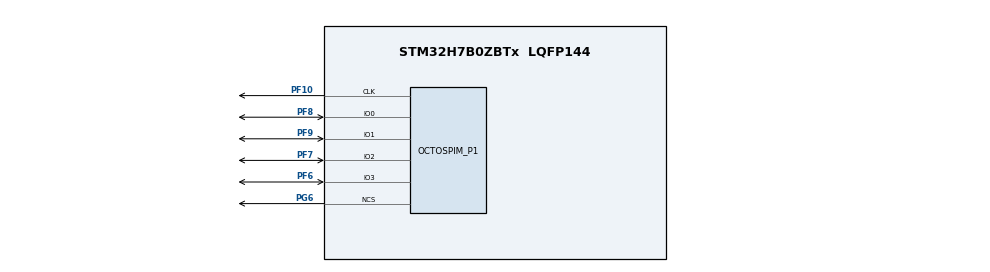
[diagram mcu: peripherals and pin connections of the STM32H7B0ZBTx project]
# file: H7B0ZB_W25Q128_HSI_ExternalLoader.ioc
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CORTEX_M7.AccessPermission_S-Cortex_Memory_Protection_Unit_Region1_Settings_S=MPU_REGION_FULL_ACCESS
CORTEX_M7.AccessPermission_S-Cortex_Memory_Protection_Unit_Region2_Settings_S=MPU_REGION_FULL_ACCESS
CORTEX_M7.AccessPermission_S-Cortex_Memory_Protection_Unit_Region3_Settings_S=MPU_REGION_FULL_ACCESS
CORTEX_M7.AccessPermission_S-Cortex_Memory_Protection_Unit_Region4_Settings_S=MPU_REGION_FULL_ACCESS
CORTEX_M7.AccessPermission_S-Cortex_Memory_Protection_Unit_Region5_Settings_S=MPU_REGION_FULL_ACCESS
CORTEX_M7.AccessPermission_S-Cortex_Memory_Protection_Unit_Region6_Settings_S=MPU_REGION_FULL_ACCESS
CORTEX_M7.AccessPermission_Spec=MPU_REGION_FULL_ACCESS
CORTEX_M7.BaseAddress_S-Cortex_Memory_Protection_Unit_Region1_Settings_S=0x90000000
CORTEX_M7.BaseAddress_S-Cortex_Memory_Protection_Unit_Region2_Settings_S=0x20000000
CORTEX_M7.BaseAddress_S-Cortex_Memory_Protection_Unit_Region3_Settings_S=0x24000000
CORTEX_M7.BaseAddress_S-Cortex_Memory_Protection_Unit_Region4_Settings_S=0x24000000
CORTEX_M7.BaseAddress_S-Cortex_Memory_Protection_Unit_Region5_Settings_S=0x30000000
CORTEX_M7.BaseAddress_S-Cortex_Memory_Protection_Unit_Region6_Settings_S=0x38000000
CORTEX_M7.BaseAddress_Spec=0x08000000
CORTEX_M7.CPU_DCache=Disabled
CORTEX_M7.CPU_ICache=Disabled
CORTEX_M7.DisableExec_S-Cortex_Memory_Protection_Unit_Region4_Settings_S=MPU_INSTRUCTION_ACCESS_ENABLE
CORTEX_M7.DisableExec_Spec=MPU_INSTRUCTION_ACCESS_ENABLE
CORTEX_M7.Enable_S-Cortex_Memory_Protection_Unit_Region1_Settings_S=MPU_REGION_ENABLE
CORTEX_M7.Enable_S-Cortex_Memory_Protection_Unit_Region2_Settings_S=MPU_REGION_ENABLE
CORTEX_M7.Enable_S-Cortex_Memory_Protection_Unit_Region3_Settings_S=MPU_REGION_ENABLE
CORTEX_M7.Enable_S-Cortex_Memory_Protection_Unit_Region4_Settings_S=MPU_REGION_ENABLE
CORTEX_M7.Enable_S-Cortex_Memory_Protection_Unit_Region5_Settings_S=MPU_REGION_ENABLE
CORTEX_M7.Enable_S-Cortex_Memory_Protection_Unit_Region6_Settings_S=MPU_REGION_ENABLE
CORTEX_M7.Enable_S-Cortex_Memory_Protection_Unit_Region7_Settings_S=__NULL
CORTEX_M7.Enable_S-Cortex_Memory_Protection_Unit_Region8_Settings_S=__NULL
CORTEX_M7.IsBufferable_S-Cortex_Memory_Protection_Unit_Region1_Settings_S=MPU_ACCESS_BUFFERABLE
CORTEX_M7.IsBufferable_S-Cortex_Memory_Protection_Unit_Region2_Settings_S=MPU_ACCESS_NOT_BUFFERABLE
CORTEX_M7.IsBufferable_S-Cortex_Memory_Protection_Unit_Region3_Settings_S=MPU_ACCESS_BUFFERABLE
CORTEX_M7.IsBufferable_S-Cortex_Memory_Protection_Unit_Region4_Settings_S=MPU_ACCESS_NOT_BUFFERABLE
CORTEX_M7.IsBufferable_S-Cortex_Memory_Protection_Unit_Region5_Settings_S=MPU_ACCESS_BUFFERABLE
CORTEX_M7.IsBufferable_S-Cortex_Memory_Protection_Unit_Region6_Settings_S=MPU_ACCESS_NOT_BUFFERABLE
CORTEX_M7.IsBufferable_Spec=MPU_ACCESS_BUFFERABLE
CORTEX_M7.IsCacheable_S-Cortex_Memory_Protection_Unit_Region1_Settings_S=MPU_ACCESS_CACHEABLE
CORTEX_M7.IsCacheable_S-Cortex_Memory_Protection_Unit_Region2_Settings_S=MPU_ACCESS_NOT_CACHEABLE
CORTEX_M7.IsCacheable_S-Cortex_Memory_Protection_Unit_Region3_Settings_S=MPU_ACCESS_CACHEABLE
CORTEX_M7.IsCacheable_S-Cortex_Memory_Protection_Unit_Region4_Settings_S=MPU_ACCESS_NOT_CACHEABLE
CORTEX_M7.IsCacheable_S-Cortex_Memory_Protection_Unit_Region5_Settings_S=MPU_ACCESS_CACHEABLE
CORTEX_M7.IsCacheable_S-Cortex_Memory_Protection_Unit_Region6_Settings_S=MPU_ACCESS_NOT_CACHEABLE
CORTEX_M7.IsCacheable_Spec=MPU_ACCESS_CACHEABLE
CORTEX_M7.IsShareable_S-Cortex_Memory_Protection_Unit_Region3_Settings_S=MPU_ACCESS_NOT_SHAREABLE
CORTEX_M7.IsShareable_S-Cortex_Memory_Protection_Unit_Region5_Settings_S=MPU_ACCESS_NOT_SHAREABLE
CORTEX_M7.IsShareable_S-Cortex_Memory_Protection_Unit_Region6_Settings_S=MPU_ACCESS_NOT_SHAREABLE
CORTEX_M7.IsShareable_Spec=MPU_ACCESS_NOT_SHAREABLE
CORTEX_M7.Size_S-Cortex_Memory_Protection_Unit_Region1_Settings_S=MPU_REGION_SIZE_128MB
CORTEX_M7.Size_S-Cortex_Memory_Protection_Unit_Region2_Settings_S=MPU_REGION_SIZE_128KB
CORTEX_M7.Size_S-Cortex_Memory_Protection_Unit_Region3_Settings_S=MPU_REGION_SIZE_1MB
CORTEX_M7.Size_S-Cortex_Memory_Protection_Unit_Region4_Settings_S=MPU_REGION_SIZE_1MB
CORTEX_M7.Size_S-Cortex_Memory_Protection_Unit_Region5_Settings_S=MPU_REGION_SIZE_128KB
CORTEX_M7.Size_S-Cortex_Memory_Protection_Unit_Region6_Settings_S=MPU_REGION_SIZE_32KB
CORTEX_M7.Size_Spec=MPU_REGION_SIZE_256KB
CORTEX_M7.SubRegionDisable_Spec=0
CORTEX_M7.default_mode_Activation=0
Mcu.Family=STM32H7
Mcu.Name=STM32H7B0ZBTx
Mcu.Package=LQFP144
NVIC.PriorityGroup=NVIC_PRIORITYGROUP_4
OCTOSPI1.ChipSelectHighTime=2
OCTOSPI1.ClockPrescaler=1
OCTOSPI1.DeviceSize=23
PA13.Mode=Serial_Wire
PA13.Signal=DEBUG_JTMS-SWDIO
PA14.Mode=Serial_Wire
PA14.Signal=DEBUG_JTCK-SWCLK
PF10.Mode=O1_P1_CLK
PF10.Signal=OCTOSPIM_P1_CLK
PF6.Mode=OCTOSPI1_IOL_Port1L
PF6.Signal=OCTOSPIM_P1_IO3
PF7.Mode=OCTOSPI1_IOL_Port1L
PF7.Signal=OCTOSPIM_P1_IO2
PF8.Mode=OCTOSPI1_IOL_Port1L
PF8.Signal=OCTOSPIM_P1_IO0
PF9.Mode=OCTOSPI1_IOL_Port1L
PF9.Signal=OCTOSPIM_P1_IO1
PG6.Mode=OCTOSPI1_Port1_NCS
PG6.Signal=OCTOSPIM_P1_NCS
ProjectManager.HeapSize=0x200
ProjectManager.StackSize=0x1000
ProjectManager.TargetToolchain=STM32CubeIDE
RCC.ADCFreq_Value=128000000
RCC.APB1Freq_Value=32000000
RCC.APB2Freq_Value=32000000
RCC.APB3Freq_Value=32000000
RCC.APB4Freq_Value=32000000
RCC.CDPPRE=RCC_APB3_DIV2
RCC.CDPPRE1=RCC_APB1_DIV2
RCC.CDPPRE2=RCC_APB2_DIV2
RCC.CortexFreq_Value=64000000
RCC.DIVM1=2
RCC.DIVM2=2
RCC.DIVM3=6
RCC.DIVN1=40
RCC.DIVN2=16
RCC.DIVN3=58
RCC.DIVP2=4
RCC.DIVP3=10
RCC.DIVQ2=8
RCC.DIVQ3=24
RCC.DIVR2=4
RCC.DIVR3=10
RCC.FDCANCLockSelection=RCC_FDCANCLKSOURCE_PLL2
RCC.HCLKFreq_Value=64000000
RCC.HSE_VALUE=25000000
RCC.LPUART1CLockSelection=RCC_LPUART1CLKSOURCE_CSI
RCC.PLL1_VCI_Range-AdvancedSettings=RCC_PLL1VCIRANGE_0
RCC.PLL1_VCO_SEL-AdvancedSettings=RCC_PLL1VCOMEDIUM
RCC.PLL2FRACN=0
RCC.PLL2_VCI_Range-AdvancedSettings=RCC_PLL2VCIRANGE_0
RCC.PLL2_VCO_SEL-AdvancedSettings=RCC_PLL2VCOWIDE
RCC.PLL3FRACN=8048
RCC.PLLFRACN=0
RCC.SAI2ACLockSelection=RCC_SAI2ACLKSOURCE_PLL3
RCC.SAI2BCLockSelection=RCC_SAI2BCLKSOURCE_PLL3
RCC.SDMMC1CLockSelection=RCC_SDMMCCLKSOURCE_PLL2
RCC.SPI123CLockSelection=RCC_SPI123CLKSOURCE_PLL2
RCC.SRDPPRE=RCC_APB4_DIV2
RCC.SYSCLKFreq_VALUE=64000000
RCC.USART234578CLockSelection=RCC_USART234578CLKSOURCE_PLL3
RCC.USBCLockSelection=RCC_USBCLKSOURCE_HSI48
RCC.USBFreq_Value=48000000
VP_MEMORYMAP_VS_MEMORYMAP.Mode=CurAppReg
VP_OCTOSPI1_VS_quad.Mode=quad_mode
board=custom

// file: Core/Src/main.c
/* USER CODE BEGIN Header */
/**
  ******************************************************************************
  * @file           : main.c
  * @brief          : Main program body
  ******************************************************************************
  * @attention
  *
  * Copyright (c) 2024 STMicroelectronics.
  * All rights reserved.
  *
  * This software is licensed under terms that can be found in the LICENSE file
  * in the root directory of this software component.
  * If no LICENSE file comes with this software, it is provided AS-IS.
  *
  ******************************************************************************
  */
/* USER CODE END Header */
#include "main.h"
#include "octospi.h"
#include "gpio.h"

/* USER CODE BEGIN Includes */
#include "W25Q128.h"
#include "stdio.h"
#include "stdlib.h"
#include "string.h"
/* USER CODE END Includes */

void SystemClock_Config(void);

/* USER CODE BEGIN 0 */
uint8_t txbuf[] = "TEST";
uint8_t txbuf2[] = "A";

HAL_StatusTypeDef ret=0;
uint8_t rxbuf[100];
/* USER CODE END 0 */

int main(void)
{

  /* MCU Configuration--------------------------------------------------------*/

  /* Reset of all peripherals, Initializes the Flash interface and the Systick. */
  HAL_Init();

  /* Configure the system clock */
  SystemClock_Config();

  /* Initialize all configured peripherals */
  MX_GPIO_Init();
  MX_OCTOSPI1_Init();

  /* Infinite loop */
  while (1)
  {

  }
}

void SystemClock_Config(void)
{
  RCC_OscInitTypeDef RCC_OscInitStruct = {0};
  RCC_ClkInitTypeDef RCC_ClkInitStruct = {0};

  /*AXI clock gating */
  RCC->CKGAENR = 0xE003FFFF;

  /** Supply configuration update enable
  */
  HAL_PWREx_ConfigSupply(PWR_LDO_SUPPLY);

  /** Configure the main internal regulator output voltage
  */
  __HAL_PWR_VOLTAGESCALING_CONFIG(PWR_REGULATOR_VOLTAGE_SCALE3);

  while(!__HAL_PWR_GET_FLAG(PWR_FLAG_VOSRDY)) {}

  /** Initializes the RCC Oscillators according to the specified parameters
  * in the RCC_OscInitTypeDef structure.
  */
  RCC_OscInitStruct.OscillatorType = RCC_OSCILLATORTYPE_HSI;
  RCC_OscInitStruct.HSIState = RCC_HSI_DIV1;
  RCC_OscInitStruct.HSICalibrationValue = 64;
  RCC_OscInitStruct.PLL.PLLState = RCC_PLL_NONE;
  if (HAL_RCC_OscConfig(&RCC_OscInitStruct) != HAL_OK)
  {
    Error_Handler();
  }

  /** Initializes the CPU, AHB and APB buses clocks
  */
  RCC_ClkInitStruct.ClockType = RCC_CLOCKTYPE_HCLK|RCC_CLOCKTYPE_SYSCLK
                              |RCC_CLOCKTYPE_PCLK1|RCC_CLOCKTYPE_PCLK2
                              |RCC_CLOCKTYPE_D3PCLK1|RCC_CLOCKTYPE_D1PCLK1;
  RCC_ClkInitStruct.SYSCLKSource = RCC_SYSCLKSOURCE_HSI;
  RCC_ClkInitStruct.SYSCLKDivider = RCC_SYSCLK_DIV1;
  RCC_ClkInitStruct.AHBCLKDivider = RCC_HCLK_DIV1;
  RCC_ClkInitStruct.APB3CLKDivider = RCC_APB3_DIV2;
  RCC_ClkInitStruct.APB1CLKDivider = RCC_APB1_DIV2;
  RCC_ClkInitStruct.APB2CLKDivider = RCC_APB2_DIV2;
  RCC_ClkInitStruct.APB4CLKDivider = RCC_APB4_DIV2;

  if (HAL_RCC_ClockConfig(&RCC_ClkInitStruct, FLASH_LATENCY_2) != HAL_OK)
  {
    Error_Handler();
  }
}

void Error_Handler(void)
{
  __disable_irq();
  while (1)
  {
  }
}
